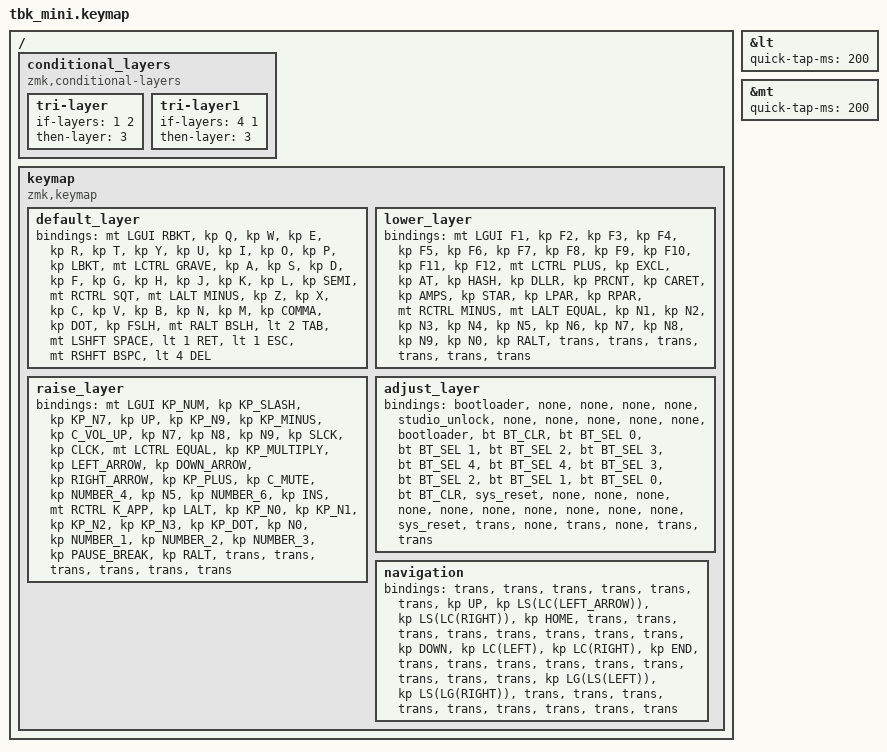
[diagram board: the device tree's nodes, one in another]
/*
 * Copyright (c) 2020 The ZMK Contributors
 *
 * SPDX-License-Identifier: MIT
 */

#include <behaviors.dtsi>
#include <dt-bindings/zmk/bt.h>
#include <dt-bindings/zmk/keys.h>

#define DEF 0
#define LWR 1
#define RSE 2
#define ADJ 3
#define NAV 4

&lt { quick-tap-ms = <200>; };

&mt { quick-tap-ms = <200>; };

/ {
    conditional_layers {
        compatible = "zmk,conditional-layers";

        tri-layer {
            if-layers = <1 2>;
            then-layer = <3>;
        };

        tri-layer1 {
            if-layers = <4 1>;
            then-layer = <3>;
        };
    };

    keymap {
        compatible = "zmk,keymap";

        default_layer {
            bindings = <
&mt LGUI RBKT  &kp Q  &kp W  &kp E  &kp R  &kp T  &kp Y  &kp U  &kp I  &kp O  &kp P  &kp LBKT  &mt LCTRL GRAVE  &kp A  &kp S  &kp D  &kp F  &kp G  &kp H  &kp J  &kp K  &kp L  &kp SEMI  &mt RCTRL SQT  &mt LALT MINUS  &kp Z  &kp X  &kp C  &kp V  &kp B  &kp N  &kp M  &kp COMMA  &kp DOT  &kp FSLH  &mt RALT BSLH  &lt 2 TAB  &mt LSHFT SPACE  &lt 1 RET  &lt 1 ESC  &mt RSHFT BSPC  &lt 4 DEL
            >;
        };

        lower_layer {
            bindings = <
&mt LGUI F1  &kp F2  &kp F3  &kp F4  &kp F5  &kp F6  &kp F7  &kp F8  &kp F9  &kp F10  &kp F11  &kp F12  &mt LCTRL PLUS  &kp EXCL  &kp AT  &kp HASH  &kp DLLR  &kp PRCNT  &kp CARET  &kp AMPS  &kp STAR  &kp LPAR  &kp RPAR  &mt RCTRL MINUS  &mt LALT EQUAL  &kp N1  &kp N2  &kp N3  &kp N4  &kp N5  &kp N6  &kp N7  &kp N8  &kp N9  &kp N0  &kp RALT  &trans  &trans  &trans  &trans  &trans  &trans
            >;
        };

        raise_layer {
            bindings = <
&mt LGUI KP_NUM  &kp KP_SLASH  &kp KP_N7  &kp UP  &kp KP_N9  &kp KP_MINUS  &kp C_VOL_UP  &kp N7  &kp N8  &kp N9  &kp SLCK  &kp CLCK  &mt LCTRL EQUAL  &kp KP_MULTIPLY  &kp LEFT_ARROW  &kp DOWN_ARROW  &kp RIGHT_ARROW  &kp KP_PLUS  &kp C_MUTE  &kp NUMBER_4  &kp N5  &kp NUMBER_6  &kp INS  &mt RCTRL K_APP  &kp LALT  &kp KP_N0  &kp KP_N1  &kp KP_N2  &kp KP_N3  &kp KP_DOT  &kp N0  &kp NUMBER_1  &kp NUMBER_2  &kp NUMBER_3  &kp PAUSE_BREAK  &kp RALT  &trans  &trans  &trans  &trans  &trans  &trans
            >;
        };

        adjust_layer {
            bindings = <
&bootloader  &none  &none  &none  &none  &studio_unlock  &none  &none  &none  &none  &none  &bootloader  &bt BT_CLR  &bt BT_SEL 0  &bt BT_SEL 1  &bt BT_SEL 2  &bt BT_SEL 3  &bt BT_SEL 4  &bt BT_SEL 4  &bt BT_SEL 3  &bt BT_SEL 2  &bt BT_SEL 1  &bt BT_SEL 0  &bt BT_CLR  &sys_reset  &none  &none  &none  &none  &none  &none  &none  &none  &none  &none  &sys_reset  &trans  &none  &trans  &none  &trans  &trans
            >;
        };

        navigation {
            bindings = <
&trans  &trans  &trans  &trans  &trans  &trans  &kp UP  &kp LS(LC(LEFT_ARROW))  &kp LS(LC(RIGHT))  &kp HOME  &trans  &trans  &trans  &trans  &trans  &trans  &trans  &trans  &kp DOWN  &kp LC(LEFT)  &kp LC(RIGHT)  &kp END  &trans  &trans  &trans  &trans  &trans  &trans  &trans  &trans  &trans  &kp LG(LS(LEFT))  &kp LS(LG(RIGHT))  &trans  &trans  &trans  &trans  &trans  &trans  &trans  &trans  &trans
            >;
        };
    };
};
